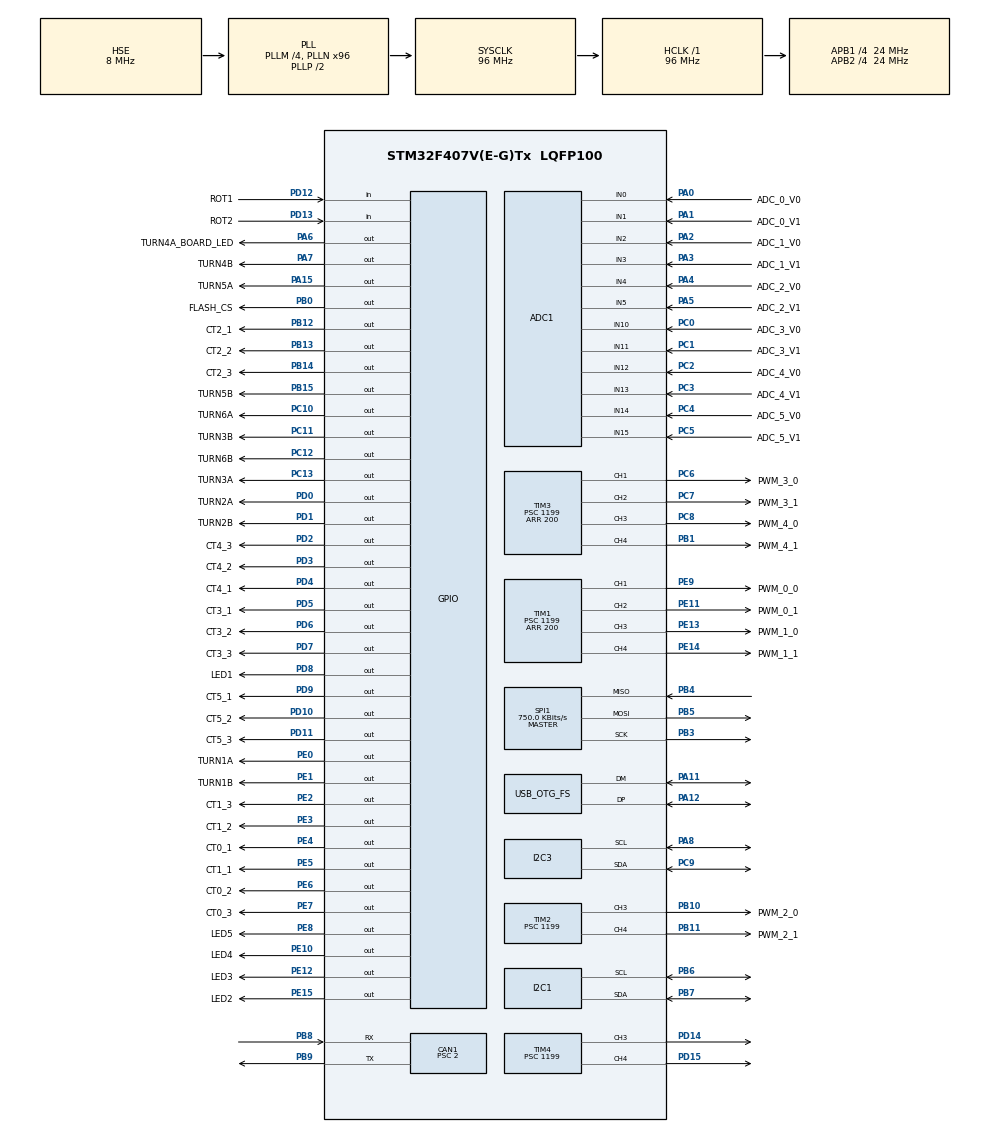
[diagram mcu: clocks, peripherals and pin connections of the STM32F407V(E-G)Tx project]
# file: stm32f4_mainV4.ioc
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ADC1.Channel-0\#ChannelRegularConversion=ADC_CHANNEL_0
ADC1.Channel-1\#ChannelRegularConversion=ADC_CHANNEL_1
ADC1.Channel-10\#ChannelRegularConversion=ADC_CHANNEL_14
ADC1.Channel-11\#ChannelRegularConversion=ADC_CHANNEL_15
ADC1.Channel-2\#ChannelRegularConversion=ADC_CHANNEL_2
ADC1.Channel-3\#ChannelRegularConversion=ADC_CHANNEL_3
ADC1.Channel-4\#ChannelRegularConversion=ADC_CHANNEL_4
ADC1.Channel-5\#ChannelRegularConversion=ADC_CHANNEL_5
ADC1.Channel-6\#ChannelRegularConversion=ADC_CHANNEL_10
ADC1.Channel-7\#ChannelRegularConversion=ADC_CHANNEL_11
ADC1.Channel-8\#ChannelRegularConversion=ADC_CHANNEL_12
ADC1.Channel-9\#ChannelRegularConversion=ADC_CHANNEL_13
ADC1.ClockPrescaler=ADC_CLOCK_SYNC_PCLK_DIV2
ADC1.DMAContinuousRequests=ENABLE
ADC1.EOCSelection=ADC_EOC_SEQ_CONV
ADC1.ExternalTrigConv=ADC_EXTERNALTRIGCONV_T8_TRGO
ADC1.ExternalTrigConvEdge=ADC_EXTERNALTRIGCONVEDGE_RISING
ADC1.NbrOfConversion=12
ADC1.NbrOfConversionFlag=1
ADC1.Rank-0\#ChannelRegularConversion=1
ADC1.Rank-1\#ChannelRegularConversion=2
ADC1.Rank-10\#ChannelRegularConversion=11
ADC1.Rank-11\#ChannelRegularConversion=12
ADC1.Rank-2\#ChannelRegularConversion=3
ADC1.Rank-3\#ChannelRegularConversion=4
ADC1.Rank-4\#ChannelRegularConversion=5
ADC1.Rank-5\#ChannelRegularConversion=6
ADC1.Rank-6\#ChannelRegularConversion=7
ADC1.Rank-7\#ChannelRegularConversion=8
ADC1.Rank-8\#ChannelRegularConversion=9
ADC1.Rank-9\#ChannelRegularConversion=10
ADC1.SamplingTime-0\#ChannelRegularConversion=ADC_SAMPLETIME_3CYCLES
ADC1.SamplingTime-1\#ChannelRegularConversion=ADC_SAMPLETIME_3CYCLES
ADC1.SamplingTime-10\#ChannelRegularConversion=ADC_SAMPLETIME_3CYCLES
ADC1.SamplingTime-11\#ChannelRegularConversion=ADC_SAMPLETIME_3CYCLES
ADC1.SamplingTime-2\#ChannelRegularConversion=ADC_SAMPLETIME_3CYCLES
ADC1.SamplingTime-3\#ChannelRegularConversion=ADC_SAMPLETIME_3CYCLES
ADC1.SamplingTime-4\#ChannelRegularConversion=ADC_SAMPLETIME_3CYCLES
ADC1.SamplingTime-5\#ChannelRegularConversion=ADC_SAMPLETIME_3CYCLES
ADC1.SamplingTime-6\#ChannelRegularConversion=ADC_SAMPLETIME_3CYCLES
ADC1.SamplingTime-7\#ChannelRegularConversion=ADC_SAMPLETIME_3CYCLES
ADC1.SamplingTime-8\#ChannelRegularConversion=ADC_SAMPLETIME_3CYCLES
ADC1.SamplingTime-9\#ChannelRegularConversion=ADC_SAMPLETIME_3CYCLES
ADC1.ScanConvMode=ENABLE
ADC1.master=1
ADC2.Channel-0\#ChannelRegularConversion=ADC_CHANNEL_0
ADC2.Channel-1\#ChannelRegularConversion=ADC_CHANNEL_1
ADC2.Channel-2\#ChannelRegularConversion=ADC_CHANNEL_2
ADC2.Channel-3\#ChannelRegularConversion=ADC_CHANNEL_3
ADC2.DMAContinuousRequests=DISABLE
ADC2.EOCSelection=ADC_EOC_SEQ_CONV
ADC2.ExternalTrigConv=ADC_SOFTWARE_START
ADC2.NbrOfConversion=4
ADC2.NbrOfConversionFlag=1
ADC2.Rank-0\#ChannelRegularConversion=1
ADC2.Rank-1\#ChannelRegularConversion=2
ADC2.Rank-2\#ChannelRegularConversion=3
ADC2.Rank-3\#ChannelRegularConversion=4
ADC2.SamplingTime-0\#ChannelRegularConversion=ADC_SAMPLETIME_3CYCLES
ADC2.SamplingTime-1\#ChannelRegularConversion=ADC_SAMPLETIME_3CYCLES
ADC2.SamplingTime-2\#ChannelRegularConversion=ADC_SAMPLETIME_3CYCLES
ADC2.SamplingTime-3\#ChannelRegularConversion=ADC_SAMPLETIME_3CYCLES
CAN1.ABOM=ENABLE
CAN1.AWUM=ENABLE
CAN1.BS1=CAN_BS1_10TQ
CAN1.CalculateBaudRate=1000000
CAN1.CalculateTimeBit=1000
CAN1.CalculateTimeQuantum=83.33333333333333
CAN1.NART=ENABLE
CAN1.Prescaler=2
CAN1.SJW=CAN_SJW_1TQ
Dma.ADC1.0.Direction=DMA_PERIPH_TO_MEMORY
Dma.ADC1.0.FIFOMode=DMA_FIFOMODE_DISABLE
Dma.ADC1.0.Instance=DMA2_Stream0
Dma.ADC1.0.MemDataAlignment=DMA_MDATAALIGN_HALFWORD
Dma.ADC1.0.MemInc=DMA_MINC_ENABLE
Dma.ADC1.0.Mode=DMA_CIRCULAR
Dma.ADC1.0.PeriphDataAlignment=DMA_PDATAALIGN_HALFWORD
Dma.ADC1.0.PeriphInc=DMA_PINC_DISABLE
Dma.ADC1.0.Priority=DMA_PRIORITY_HIGH
Dma.ADC2.1.Direction=DMA_PERIPH_TO_MEMORY
Dma.ADC2.1.FIFOMode=DMA_FIFOMODE_DISABLE
Dma.ADC2.1.Instance=DMA2_Stream2
Dma.ADC2.1.MemDataAlignment=DMA_MDATAALIGN_HALFWORD
Dma.ADC2.1.MemInc=DMA_MINC_ENABLE
Dma.ADC2.1.Mode=DMA_NORMAL
Dma.ADC2.1.PeriphDataAlignment=DMA_PDATAALIGN_HALFWORD
Dma.ADC2.1.PeriphInc=DMA_PINC_DISABLE
Dma.ADC2.1.Priority=DMA_PRIORITY_MEDIUM
Dma.Request0=ADC1
Dma.Request1=ADC2
FREERTOS.HEAP_NUMBER=1
FREERTOS.INCLUDE_uxTaskGetStackHighWaterMark=1
FREERTOS.INCLUDE_uxTaskGetStackHighWaterMark2=0
FREERTOS.INCLUDE_uxTaskPriorityGet=1
FREERTOS.INCLUDE_vTaskDelay=1
FREERTOS.INCLUDE_vTaskDelayUntil=1
FREERTOS.INCLUDE_vTaskDelete=0
FREERTOS.INCLUDE_vTaskPrioritySet=1
FREERTOS.INCLUDE_vTaskSuspend=1
FREERTOS.INCLUDE_xTaskGetHandle=0
FREERTOS.MEMORY_ALLOCATION=1
FREERTOS.Tasks01=uiTask,-1,256,StartUiTask,As weak,NULL,Static,defaultTaskBuffer,defaultTaskControlBlock;ctrlTask,2,256,StartCtrlTask,As external,NULL,Static,ctrlTaskBuffer,ctrlTaskControlBlock;usbTask,-2,384,StartUsbTask,As external,NULL,Static,usbTaskBuffer,usbTaskControlBlock;ina3221_task,1,172,ina3221_task_start,As weak,NULL,Static,ina3221_taskBuffer,ina3221_taskControlBlock;ledTask,3,128,start_led_task,As weak,NULL,Static,ledTaskBuffer,ledTaskControlBlock;oscillo,0,128,StartOscillo,As weak,NULL,Static,oscilloBuffer,oscilloControlBlock;oamTask,-2,256,StartOamTask,As external,NULL,Static,oamTaskBuffer,oamTaskControlBlock
FREERTOS.configCHECK_FOR_STACK_OVERFLOW=2
FREERTOS.configENABLE_BACKWARD_COMPATIBILITY=0
FREERTOS.configENABLE_FPU=0
FREERTOS.configGENERATE_RUN_TIME_STATS=1
FREERTOS.configIDLE_SHOULD_YIELD=0
FREERTOS.configRECORD_STACK_HIGH_ADDRESS=1
FREERTOS.configTOTAL_HEAP_SIZE=4096
FREERTOS.configUSE_MUTEXES=0
FREERTOS.configUSE_NEWLIB_REENTRANT=0
FREERTOS.configUSE_STATS_FORMATTING_FUNCTIONS=1
FREERTOS.configUSE_TRACE_FACILITY=1
FREERTOS.copyHeapFile=0
I2C1.I2C_Mode=I2C_Fast
I2C3.I2C_Mode=I2C_Fast
Mcu.Family=STM32F4
Mcu.Name=STM32F407V(E-G)Tx
Mcu.Package=LQFP100
NVIC.CAN1_RX0_IRQn=true\:5\:0\:false\:false\:true\:true\:true\:true\:true
NVIC.CAN1_RX1_IRQn=true\:5\:0\:false\:false\:true\:true\:true\:true\:true
NVIC.CAN1_SCE_IRQn=true\:5\:0\:false\:false\:true\:true\:true\:true\:true
NVIC.CAN1_TX_IRQn=true\:5\:0\:false\:false\:true\:true\:true\:true\:true
NVIC.DMA2_Stream0_IRQn=true\:5\:0\:true\:false\:true\:false\:false\:true\:true
NVIC.DMA2_Stream2_IRQn=true\:5\:0\:false\:false\:true\:true\:true\:true\:true
NVIC.I2C1_ER_IRQn=true\:5\:0\:false\:false\:true\:true\:true\:true\:true
NVIC.I2C1_EV_IRQn=true\:5\:0\:false\:false\:true\:true\:true\:true\:true
NVIC.OTG_FS_IRQn=true\:10\:0\:true\:false\:true\:false\:false\:true\:true
NVIC.PriorityGroup=NVIC_PRIORITYGROUP_4
NVIC.TIM1_UP_TIM10_IRQn=true\:5\:0\:true\:false\:true\:true\:true\:true\:true
NVIC.TIM5_IRQn=true\:7\:0\:true\:false\:true\:true\:true\:true\:true
NVIC.TIM7_IRQn=true\:15\:0\:false\:false\:true\:false\:false\:true\:true
NVIC.TimeBase=TIM7_IRQn
NVIC.TimeBaseIP=TIM7
PA0-WKUP.GPIO_Label=ADC_0_V0
PA0-WKUP.Signal=ADCx_IN0
PA1.GPIO_Label=ADC_0_V1
PA1.Signal=ADCx_IN1
PA11.Mode=Device_Only
PA11.Signal=USB_OTG_FS_DM
PA12.Mode=Device_Only
PA12.Signal=USB_OTG_FS_DP
PA13.Mode=Serial_Wire
PA13.Signal=SYS_JTMS-SWDIO
PA14.Mode=Serial_Wire
PA14.Signal=SYS_JTCK-SWCLK
PA15.GPIO_Label=TURN5A
PA15.Signal=GPIO_Output
PA2.GPIO_Label=ADC_1_V0
PA2.Signal=ADCx_IN2
PA3.GPIO_Label=ADC_1_V1
PA3.Signal=ADCx_IN3
PA4.GPIO_Label=ADC_2_V0
PA4.Signal=ADCx_IN4
PA5.GPIO_Label=ADC_2_V1
PA5.Signal=ADCx_IN5
PA6.GPIO_Label=TURN4A_BOARD_LED
PA6.Signal=GPIO_Output
PA7.GPIO_Label=TURN4B
PA7.Signal=GPIO_Output
PA8.Mode=I2C
PA8.Signal=I2C3_SCL
PB0.GPIO_Label=FLASH_CS
PB0.Signal=GPIO_Output
PB1.GPIO_Label=PWM_4_1
PB1.Signal=S_TIM3_CH4
PB10.GPIO_Label=PWM_2_0
PB10.Signal=S_TIM2_CH3
PB11.GPIO_Label=PWM_2_1
PB11.Signal=S_TIM2_CH4
PB12.GPIO_Label=CT2_1
PB12.Signal=GPIO_Output
PB13.GPIO_Label=CT2_2
PB13.Signal=GPIO_Output
PB14.GPIO_Label=CT2_3
PB14.Signal=GPIO_Output
PB15.GPIO_Label=TURN5B
PB15.Signal=GPIO_Output
PB3.Mode=Full_Duplex_Master
PB3.Signal=SPI1_SCK
PB4.Mode=Full_Duplex_Master
PB4.Signal=SPI1_MISO
PB5.Mode=Full_Duplex_Master
PB5.Signal=SPI1_MOSI
PB6.Mode=I2C
PB6.Signal=I2C1_SCL
PB7.Mode=I2C
PB7.Signal=I2C1_SDA
PB8.Mode=CAN_Activate
PB8.Signal=CAN1_RX
PB9.Mode=CAN_Activate
PB9.Signal=CAN1_TX
PC0.GPIO_Label=ADC_3_V0
PC0.Signal=ADCx_IN10
PC1.GPIO_Label=ADC_3_V1
PC1.Signal=ADCx_IN11
PC10.GPIO_Label=TURN6A
PC10.Signal=GPIO_Output
PC11.GPIO_Label=TURN3B
PC11.Signal=GPIO_Output
PC12.GPIO_Label=TURN6B
PC12.Signal=GPIO_Output
PC13-ANTI_TAMP.GPIO_Label=TURN3A
PC13-ANTI_TAMP.Signal=GPIO_Output
PC14-OSC32_IN.Mode=LSE-External-Oscillator
PC14-OSC32_IN.Signal=RCC_OSC32_IN
PC15-OSC32_OUT.Mode=LSE-External-Oscillator
PC15-OSC32_OUT.Signal=RCC_OSC32_OUT
PC2.GPIO_Label=ADC_4_V0
PC2.Signal=ADCx_IN12
PC3.GPIO_Label=ADC_4_V1
PC3.Signal=ADCx_IN13
PC4.GPIO_Label=ADC_5_V0
PC4.Signal=ADCx_IN14
PC5.GPIO_Label=ADC_5_V1
PC5.Signal=ADCx_IN15
PC6.GPIO_Label=PWM_3_0
PC6.Signal=S_TIM3_CH1
PC7.GPIO_Label=PWM_3_1
PC7.Signal=S_TIM3_CH2
PC8.GPIO_Label=PWM_4_0
PC8.Signal=S_TIM3_CH3
PC9.Mode=I2C
PC9.Signal=I2C3_SDA
PD0.GPIO_Label=TURN2A
PD0.Signal=GPIO_Output
PD1.GPIO_Label=TURN2B
PD1.Signal=GPIO_Output
PD10.GPIO_Label=CT5_2
PD10.Signal=GPIO_Output
PD11.GPIO_Label=CT5_3
PD11.Signal=GPIO_Output
PD12.GPIO_Label=ROT1
PD12.Signal=GPIO_Input
PD13.GPIO_Label=ROT2
PD13.Signal=GPIO_Input
PD14.Signal=S_TIM4_CH3
PD15.Signal=S_TIM4_CH4
PD2.GPIO_Label=CT4_3
PD2.Signal=GPIO_Output
PD3.GPIO_Label=CT4_2
PD3.Signal=GPIO_Output
PD4.GPIO_Label=CT4_1
PD4.Signal=GPIO_Output
PD5.GPIO_Label=CT3_1
PD5.Signal=GPIO_Output
PD6.GPIO_Label=CT3_2
PD6.Signal=GPIO_Output
PD7.GPIO_Label=CT3_3
PD7.Signal=GPIO_Output
PD8.GPIO_Label=LED1
PD8.Signal=GPIO_Output
PD9.GPIO_Label=CT5_1
PD9.Signal=GPIO_Output
PE0.GPIO_Label=TURN1A
PE0.Signal=GPIO_Output
PE1.GPIO_Label=TURN1B
PE1.Signal=GPIO_Output
PE10.GPIO_Label=LED4
PE10.Signal=GPIO_Output
PE11.GPIO_Label=PWM_0_1
PE11.Signal=S_TIM1_CH2
PE12.GPIO_Label=LED3
PE12.Signal=GPIO_Output
PE13.GPIO_Label=PWM_1_0
PE13.GPIO_Speed=GPIO_SPEED_FREQ_LOW
PE13.Signal=S_TIM1_CH3
PE14.GPIO_Label=PWM_1_1
PE14.GPIO_Speed=GPIO_SPEED_FREQ_LOW
PE14.Signal=S_TIM1_CH4
PE15.GPIO_Label=LED2
PE15.Signal=GPIO_Output
PE2.GPIO_Label=CT1_3
PE2.Signal=GPIO_Output
PE3.GPIO_Label=CT1_2
PE3.Signal=GPIO_Output
PE4.GPIO_Label=CT0_1
PE4.Signal=GPIO_Output
PE5.GPIO_Label=CT1_1
PE5.Signal=GPIO_Output
PE6.GPIO_Label=CT0_2
PE6.Signal=GPIO_Output
PE7.GPIO_Label=CT0_3
PE7.Signal=GPIO_Output
PE8.GPIO_Label=LED5
PE8.Signal=GPIO_Output
PE9.GPIO_Label=PWM_0_0
PE9.Signal=S_TIM1_CH1
PH0-OSC_IN.Mode=HSE-External-Oscillator
PH0-OSC_IN.Signal=RCC_OSC_IN
PH1-OSC_OUT.Mode=HSE-External-Oscillator
PH1-OSC_OUT.Signal=RCC_OSC_OUT
ProjectManager.HeapSize=0x200
ProjectManager.StackSize=0x400
ProjectManager.TargetToolchain=STM32CubeIDE
RCC.48MHZClocksFreq_Value=48000000
RCC.AHBFreq_Value=96000000
RCC.APB1CLKDivider=RCC_HCLK_DIV4
RCC.APB1Freq_Value=24000000
RCC.APB1TimFreq_Value=48000000
RCC.APB2CLKDivider=RCC_HCLK_DIV4
RCC.APB2Freq_Value=24000000
RCC.APB2TimFreq_Value=48000000
RCC.CortexFreq_Value=96000000
RCC.HCLKFreq_Value=96000000
RCC.HSE_VALUE=8000000
RCC.HSI_VALUE=16000000
RCC.PLLM=4
RCC.PLLN=96
RCC.RCC_RTC_Clock_Source=RCC_RTCCLKSOURCE_LSE
RCC.RCC_RTC_Clock_SourceVirtual=RCC_RTCCLKSOURCE_LSE
RCC.SYSCLKFreq_VALUE=96000000
RCC.SYSCLKSource=RCC_SYSCLKSOURCE_PLLCLK
RCC.VCOOutputFreq_Value=192000000
SH.ADCx_IN0.0=ADC1_IN0,IN0
SH.ADCx_IN0.1=ADC2_IN0,IN0
SH.ADCx_IN1.0=ADC1_IN1,IN1
SH.ADCx_IN1.1=ADC2_IN1,IN1
SH.ADCx_IN10.0=ADC1_IN10,IN10
SH.ADCx_IN11.0=ADC1_IN11,IN11
SH.ADCx_IN12.0=ADC1_IN12,IN12
SH.ADCx_IN13.0=ADC1_IN13,IN13
SH.ADCx_IN14.0=ADC1_IN14,IN14
SH.ADCx_IN15.0=ADC1_IN15,IN15
SH.ADCx_IN2.0=ADC1_IN2,IN2
SH.ADCx_IN2.1=ADC2_IN2,IN2
SH.ADCx_IN3.0=ADC1_IN3,IN3
SH.ADCx_IN3.1=ADC2_IN3,IN3
SH.ADCx_IN4.0=ADC1_IN4,IN4
SH.ADCx_IN5.0=ADC1_IN5,IN5
SH.S_TIM1_CH1.0=TIM1_CH1,PWM Generation1 CH1
SH.S_TIM1_CH2.0=TIM1_CH2,PWM Generation2 CH2
SH.S_TIM1_CH3.0=TIM1_CH3,PWM Generation3 CH3
SH.S_TIM1_CH4.0=TIM1_CH4,PWM Generation4 CH4
SH.S_TIM2_CH3.0=TIM2_CH3,PWM Generation3 CH3
SH.S_TIM2_CH4.0=TIM2_CH4,PWM Generation4 CH4
SH.S_TIM3_CH1.0=TIM3_CH1,PWM Generation1 CH1
SH.S_TIM3_CH2.0=TIM3_CH2,PWM Generation2 CH2
SH.S_TIM3_CH3.0=TIM3_CH3,PWM Generation3 CH3
SH.S_TIM3_CH4.0=TIM3_CH4,PWM Generation4 CH4
SH.S_TIM4_CH3.0=TIM4_CH3,PWM Generation3 CH3
SH.S_TIM4_CH4.0=TIM4_CH4,PWM Generation4 CH4
SPI1.BaudRatePrescaler=SPI_BAUDRATEPRESCALER_32
SPI1.CalculateBaudRate=750.0 KBits/s
SPI1.Direction=SPI_DIRECTION_2LINES
SPI1.Mode=SPI_MODE_MASTER
SPI1.VirtualType=VM_MASTER
TIM1.AutoReloadPreload=TIM_AUTORELOAD_PRELOAD_ENABLE
TIM1.Channel-PWM\ Generation1\ CH1=TIM_CHANNEL_1
TIM1.Channel-PWM\ Generation2\ CH2=TIM_CHANNEL_2
TIM1.Channel-PWM\ Generation3\ CH3=TIM_CHANNEL_3
TIM1.Channel-PWM\ Generation4\ CH4=TIM_CHANNEL_4
TIM1.CounterMode=TIM_COUNTERMODE_CENTERALIGNED3
TIM1.OffStateIDLEMode=TIM_OSSI_DISABLE
TIM1.Period=200
TIM1.Prescaler=1199
TIM1.TIM_MasterOutputTrigger=TIM_TRGO_UPDATE
TIM1.TIM_MasterSlaveMode=TIM_MASTERSLAVEMODE_ENABLE
TIM2.AutoReloadPreload=TIM_AUTORELOAD_PRELOAD_ENABLE
TIM2.Channel-PWM\ Generation3\ CH3=TIM_CHANNEL_3
TIM2.Channel-PWM\ Generation4\ CH4=TIM_CHANNEL_4
TIM2.CounterMode=TIM_COUNTERMODE_CENTERALIGNED3
TIM2.Period=200
TIM2.Prescaler=1199
TIM2.TIM_MasterOutputTrigger=TIM_TRGO_RESET
TIM2.TIM_MasterSlaveMode=TIM_MASTERSLAVEMODE_DISABLE
TIM3.AutoReloadPreload=TIM_AUTORELOAD_PRELOAD_ENABLE
TIM3.Channel-PWM\ Generation1\ CH1=TIM_CHANNEL_1
TIM3.Channel-PWM\ Generation2\ CH2=TIM_CHANNEL_2
TIM3.Channel-PWM\ Generation3\ CH3=TIM_CHANNEL_3
TIM3.Channel-PWM\ Generation4\ CH4=TIM_CHANNEL_4
TIM3.CounterMode=TIM_COUNTERMODE_CENTERALIGNED3
TIM3.Period=200
TIM3.Prescaler=1199
TIM3.TIM_MasterOutputTrigger=TIM_TRGO_RESET
TIM4.AutoReloadPreload=TIM_AUTORELOAD_PRELOAD_ENABLE
TIM4.Channel-PWM\ Generation3\ CH3=TIM_CHANNEL_3
TIM4.Channel-PWM\ Generation4\ CH4=TIM_CHANNEL_4
TIM4.CounterMode=TIM_COUNTERMODE_CENTERALIGNED3
TIM4.Period=200
TIM4.Prescaler=1199
TIM5.AutoReloadPreload=TIM_AUTORELOAD_PRELOAD_ENABLE
TIM5.Channel-Output\ Compare1\ No\ Output=TIM_CHANNEL_1
TIM5.OCMode_1=TIM_OCMODE_ACTIVE
TIM5.Period=10000
TIM5.Pulse-Output\ Compare1\ No\ Output=2900
TIM5.TIM_MasterOutputTrigger=TIM_TRGO_UPDATE
TIM5.TIM_MasterSlaveMode=TIM_MASTERSLAVEMODE_ENABLE
TIM8.AutoReloadPreload=TIM_AUTORELOAD_PRELOAD_ENABLE
TIM8.Period=199
TIM8.Prescaler=1199
TIM8.TIM_MasterOutputTrigger=TIM_TRGO_UPDATE
TIM8.TIM_MasterSlaveMode=TIM_MASTERSLAVEMODE_ENABLE
USB_DEVICE.APP_RX_DATA_SIZE-CDC_FS=512
USB_DEVICE.APP_TX_DATA_SIZE-CDC_FS=512
USB_DEVICE.CLASS_NAME_FS=CDC
USB_DEVICE.VirtualMode-CDC_FS=Cdc
USB_DEVICE.VirtualModeFS=Cdc_FS
USB_OTG_FS.VirtualMode=Device_Only
VP_FREERTOS_VS_CMSIS_V1.Mode=CMSIS_V1
VP_RTC_VS_RTC_Activate.Mode=RTC_Enabled
VP_RTC_VS_RTC_Calendar.Mode=RTC_Calendar
VP_SYS_VS_tim7.Mode=TIM7
VP_TIM12_VS_ClockSourceITR.Mode=TriggerSource_ITR0
VP_TIM1_VS_ClockSourceINT.Mode=Internal
VP_TIM2_VS_ClockSourceINT.Mode=Internal
VP_TIM2_VS_ClockSourceITR.Mode=TriggerSource_ITR0
VP_TIM3_VS_ClockSourceINT.Mode=Internal
VP_TIM3_VS_ClockSourceITR.Mode=TriggerSource_ITR0
VP_TIM3_VS_ControllerModeTrigger.Mode=Trigger Mode
VP_TIM4_VS_ClockSourceINT.Mode=Internal
VP_TIM5_VS_ClockSourceINT.Mode=Internal
VP_TIM5_VS_no_output1.Mode=Output Compare1 No Output
VP_TIM8_VS_ClockSourceINT.Mode=Internal
VP_TIM8_VS_ClockSourceITR.Mode=TriggerSource_ITR0
VP_TIM8_VS_ControllerModeReset.Mode=Reset Mode
VP_USB_DEVICE_VS_USB_DEVICE_CDC_FS.Mode=CDC_FS
board=custom

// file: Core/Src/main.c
/* USER CODE BEGIN Header */
/**
  ******************************************************************************
  * @file           : main.c
  * @brief          : Main program body
  ******************************************************************************
  * @attention
  *
  * <h2><center>&copy; Copyright (c) 2020 STMicroelectronics.
  * All rights reserved.</center></h2>
  *
  * This software component is licensed by ST under BSD 3-Clause license,
  * the "License"; You may not use this file except in compliance with the
  * License. You may obtain a copy of the License at:
  *                        opensource.org/licenses/BSD-3-Clause
  *
  ******************************************************************************
  */
/* USER CODE END Header */
#include "main.h"
#include "cmsis_os.h"
#include "usb_device.h"

/* USER CODE BEGIN Includes */
//#include "../../../disp_tft/ssd1306_tests.h"
//#include "../../../disp_tft/ssd1306.h"
//#include "../../../BLE/bletask.h"
#include <memory.h>

#include "trainctl_iface.h"
//#include "traincontrol.h"
//#include "canton.h"
//#include "stm32/txrxtask.h"
#include "stm32/usbtask.h"
//#include "stm32/taskauto.h"
#include "stm32/taskctrl.h"
#include "stm32/taskdisp.h"
//#include "../../../stm32dev/ina3221/ina3221.h"
#include "msg/notif.h"
#include "config/conf_canton.h"

/* USER CODE END Includes */

/* USER CODE BEGIN PTD */

volatile uint8_t oscillo_evtt1;

/* USER CODE END PTD */

ADC_HandleTypeDef hadc1;
ADC_HandleTypeDef hadc2;
DMA_HandleTypeDef hdma_adc1;
DMA_HandleTypeDef hdma_adc2;

CAN_HandleTypeDef hcan1;

I2C_HandleTypeDef hi2c1;
I2C_HandleTypeDef hi2c3;

RTC_HandleTypeDef hrtc;

SPI_HandleTypeDef hspi1;

TIM_HandleTypeDef htim1;
TIM_HandleTypeDef htim2;
TIM_HandleTypeDef htim3;
TIM_HandleTypeDef htim4;
TIM_HandleTypeDef htim5;
TIM_HandleTypeDef htim8;
TIM_HandleTypeDef htim12;

osThreadId uiTaskHandle;
uint32_t defaultTaskBuffer[ 256 ];
osStaticThreadDef_t defaultTaskControlBlock;
osThreadId ctrlTaskHandle;
uint32_t ctrlTaskBuffer[ 256 ];
osStaticThreadDef_t ctrlTaskControlBlock;
osThreadId usbTaskHandle;
uint32_t usbTaskBuffer[ 384 ];
osStaticThreadDef_t usbTaskControlBlock;
osThreadId ina3221_taskHandle;
uint32_t ina3221_taskBuffer[ 172 ];
osStaticThreadDef_t ina3221_taskControlBlock;
osThreadId ledTaskHandle;
uint32_t ledTaskBuffer[ 128 ];
osStaticThreadDef_t ledTaskControlBlock;
osThreadId oscilloHandle;
uint32_t oscilloBuffer[ 128 ];
osStaticThreadDef_t oscilloControlBlock;
osThreadId oamTaskHandle;
uint32_t oamTaskBuffer[ 256 ];
osStaticThreadDef_t oamTaskControlBlock;
/* USER CODE BEGIN PV */

uint32_t defaultTaskBuffer[] __attribute__((section(".ccmram")));
uint32_t ledTaskBuffer[] __attribute__((section(".ccmram")));
uint32_t oscilloBuffer[] __attribute__((section(".ccmram")));
uint32_t usbTaskBuffer[] __attribute__((section(".ccmram")));
uint32_t ina3221_taskBuffer[] __attribute__((section(".ccmram")));
uint32_t ctrlTaskBuffer[] __attribute__((section(".ccmram")));
uint32_t oamTaskBuffer[] __attribute__((section(".ccmram")));

/* USER CODE END PV */

void SystemClock_Config(void);
static void MX_GPIO_Init(void);
static void MX_DMA_Init(void);
static void MX_ADC1_Init(void);
static void MX_TIM1_Init(void);
static void MX_TIM2_Init(void);
static void MX_TIM3_Init(void);
static void MX_RTC_Init(void);
static void MX_TIM4_Init(void);
static void MX_TIM8_Init(void);
static void MX_TIM12_Init(void);
static void MX_CAN1_Init(void);
static void MX_ADC2_Init(void);
static void MX_TIM5_Init(void);
static void MX_SPI1_Init(void);
static void MX_I2C3_Init(void);
static void MX_I2C1_Init(void);
void StartUiTask(void const * argument);
extern void StartCtrlTask(void const * argument);
extern void StartUsbTask(void const * argument);
void ina3221_task_start(void const * argument);
void start_led_task(void const * argument);
void StartOscillo(void const * argument);
extern void StartOamTask(void const * argument);

/* USER CODE BEGIN PFP */

__weak void tim5_elapsed(void)
{

}
/* USER CODE END PFP */

/* USER CODE BEGIN 0 */
/*
uint32_t GetCurrentMicro(void)
{
  uint32_t m0 = HAL_GetTick();
  uint32_t u0 = SysTick->LOAD - SysTick->VAL;
  uint32_t m1 = HAL_GetTick();
  uint32_t u1 = SysTick->LOAD - SysTick->VAL;

  if (m1 > m0) {
    return ( m1 * 1000 + (u1 * 1000) / SysTick->LOAD);
  } else {
    return ( m0 * 1000 + (u0 * 1000) / SysTick->LOAD);
  }
}
*/

/* USER CODE END 0 */

int main(void)
{

  /* MCU Configuration--------------------------------------------------------*/

  /* Reset of all peripherals, Initializes the Flash interface and the Systick. */
  HAL_Init();

  /* Configure the system clock */
  SystemClock_Config();

  /* Initialize all configured peripherals */
  MX_GPIO_Init();
  MX_DMA_Init();
  MX_ADC1_Init();
  MX_TIM1_Init();
  MX_TIM2_Init();
  MX_TIM3_Init();
  MX_RTC_Init();
  MX_TIM4_Init();
  MX_TIM8_Init();
  MX_TIM12_Init();
  MX_CAN1_Init();
  MX_ADC2_Init();
  MX_TIM5_Init();
  MX_SPI1_Init();
  MX_I2C3_Init();
  MX_I2C1_Init();

  /* Create the thread(s) */
  /* definition and creation of uiTask */
  osThreadStaticDef(uiTask, StartUiTask, osPriorityBelowNormal, 0, 256, defaultTaskBuffer, &defaultTaskControlBlock);
  uiTaskHandle = osThreadCreate(osThread(uiTask), NULL);

  /* definition and creation of ctrlTask */
  osThreadStaticDef(ctrlTask, StartCtrlTask, osPriorityHigh, 0, 256, ctrlTaskBuffer, &ctrlTaskControlBlock);
  ctrlTaskHandle = osThreadCreate(osThread(ctrlTask), NULL);

  /* definition and creation of usbTask */
  osThreadStaticDef(usbTask, StartUsbTask, osPriorityLow, 0, 384, usbTaskBuffer, &usbTaskControlBlock);
  usbTaskHandle = osThreadCreate(osThread(usbTask), NULL);

  /* definition and creation of ina3221_task */
  osThreadStaticDef(ina3221_task, ina3221_task_start, osPriorityAboveNormal, 0, 172, ina3221_taskBuffer, &ina3221_taskControlBlock);
  ina3221_taskHandle = osThreadCreate(osThread(ina3221_task), NULL);

  /* definition and creation of ledTask */
  osThreadStaticDef(ledTask, start_led_task, osPriorityRealtime, 0, 128, ledTaskBuffer, &ledTaskControlBlock);
  ledTaskHandle = osThreadCreate(osThread(ledTask), NULL);

  /* definition and creation of oscillo */
  osThreadStaticDef(oscillo, StartOscillo, osPriorityNormal, 0, 128, oscilloBuffer, &oscilloControlBlock);
  oscilloHandle = osThreadCreate(osThread(oscillo), NULL);

  /* definition and creation of oamTask */
  osThreadStaticDef(oamTask, StartOamTask, osPriorityLow, 0, 256, oamTaskBuffer, &oamTaskControlBlock);
  oamTaskHandle = osThreadCreate(osThread(oamTask), NULL);

  /* Start scheduler */
  osKernelStart();

  /* We should never get here as control is now taken by the scheduler */
  /* Infinite loop */
  while (1)
  {

  }
}

void SystemClock_Config(void)
{
  RCC_OscInitTypeDef RCC_OscInitStruct = {0};
  RCC_ClkInitTypeDef RCC_ClkInitStruct = {0};

  /** Configure the main internal regulator output voltage
  */
  __HAL_RCC_PWR_CLK_ENABLE();
  __HAL_PWR_VOLTAGESCALING_CONFIG(PWR_REGULATOR_VOLTAGE_SCALE1);

  /** Initializes the RCC Oscillators according to the specified parameters
  * in the RCC_OscInitTypeDef structure.
  */
  RCC_OscInitStruct.OscillatorType = RCC_OSCILLATORTYPE_HSE|RCC_OSCILLATORTYPE_LSE;
  RCC_OscInitStruct.HSEState = RCC_HSE_ON;
  RCC_OscInitStruct.LSEState = RCC_LSE_ON;
  RCC_OscInitStruct.PLL.PLLState = RCC_PLL_ON;
  RCC_OscInitStruct.PLL.PLLSource = RCC_PLLSOURCE_HSE;
  RCC_OscInitStruct.PLL.PLLM = 4;
  RCC_OscInitStruct.PLL.PLLN = 96;
  RCC_OscInitStruct.PLL.PLLP = RCC_PLLP_DIV2;
  RCC_OscInitStruct.PLL.PLLQ = 4;
  if (HAL_RCC_OscConfig(&RCC_OscInitStruct) != HAL_OK)
  {
    Error_Handler();
  }

  /** Initializes the CPU, AHB and APB buses clocks
  */
  RCC_ClkInitStruct.ClockType = RCC_CLOCKTYPE_HCLK|RCC_CLOCKTYPE_SYSCLK
                              |RCC_CLOCKTYPE_PCLK1|RCC_CLOCKTYPE_PCLK2;
  RCC_ClkInitStruct.SYSCLKSource = RCC_SYSCLKSOURCE_PLLCLK;
  RCC_ClkInitStruct.AHBCLKDivider = RCC_SYSCLK_DIV1;
  RCC_ClkInitStruct.APB1CLKDivider = RCC_HCLK_DIV4;
  RCC_ClkInitStruct.APB2CLKDivider = RCC_HCLK_DIV4;

  if (HAL_RCC_ClockConfig(&RCC_ClkInitStruct, FLASH_LATENCY_3) != HAL_OK)
  {
    Error_Handler();
  }
}

static void MX_ADC1_Init(void)
{

  ADC_ChannelConfTypeDef sConfig = {0};

  /** Configure the global features of the ADC (Clock, Resolution, Data Alignment and number of conversion)
  */
  hadc1.Instance = ADC1;
  hadc1.Init.ClockPrescaler = ADC_CLOCK_SYNC_PCLK_DIV2;
  hadc1.Init.Resolution = ADC_RESOLUTION_12B;
  hadc1.Init.ScanConvMode = ENABLE;
  hadc1.Init.ContinuousConvMode = DISABLE;
  hadc1.Init.DiscontinuousConvMode = DISABLE;
  hadc1.Init.ExternalTrigConvEdge = ADC_EXTERNALTRIGCONVEDGE_RISING;
  hadc1.Init.ExternalTrigConv = ADC_EXTERNALTRIGCONV_T8_TRGO;
  hadc1.Init.DataAlign = ADC_DATAALIGN_RIGHT;
  hadc1.Init.NbrOfConversion = 12;
  hadc1.Init.DMAContinuousRequests = ENABLE;
  hadc1.Init.EOCSelection = ADC_EOC_SEQ_CONV;
  if (HAL_ADC_Init(&hadc1) != HAL_OK)
  {
    Error_Handler();
  }

  /** Configure for the selected ADC regular channel its corresponding rank in the sequencer and its sample time.
  */
  sConfig.Channel = ADC_CHANNEL_0;
  sConfig.Rank = 1;
  sConfig.SamplingTime = ADC_SAMPLETIME_3CYCLES;
  if (HAL_ADC_ConfigChannel(&hadc1, &sConfig) != HAL_OK)
  {
    Error_Handler();
  }

  /** Configure for the selected ADC regular channel its corresponding rank in the sequencer and its sample time.
  */
  sConfig.Channel = ADC_CHANNEL_1;
  sConfig.Rank = 2;
  if (HAL_ADC_ConfigChannel(&hadc1, &sConfig) != HAL_OK)
  {
    Error_Handler();
  }

  /** Configure for the selected ADC regular channel its corresponding rank in the sequencer and its sample time.
  */
  sConfig.Channel = ADC_CHANNEL_2;
  sConfig.Rank = 3;
  if (HAL_ADC_ConfigChannel(&hadc1, &sConfig) != HAL_OK)
  {
    Error_Handler();
  }

  /** Configure for the selected ADC regular channel its corresponding rank in the sequencer and its sample time.
  */
  sConfig.Channel = ADC_CHANNEL_3;
  sConfig.Rank = 4;
  if (HAL_ADC_ConfigChannel(&hadc1, &sConfig) != HAL_OK)
  {
    Error_Handler();
  }

  /** Configure for the selected ADC regular channel its corresponding rank in the sequencer and its sample time.
  */
  sConfig.Channel = ADC_CHANNEL_4;
  sConfig.Rank = 5;
  if (HAL_ADC_ConfigChannel(&hadc1, &sConfig) != HAL_OK)
  {
    Error_Handler();
  }

  /** Configure for the selected ADC regular channel its corresponding rank in the sequencer and its sample time.
  */
  sConfig.Channel = ADC_CHANNEL_5;
  sConfig.Rank = 6;
  if (HAL_ADC_ConfigChannel(&hadc1, &sConfig) != HAL_OK)
  {
    Error_Handler();
  }

  /** Configure for the selected ADC regular channel its corresponding rank in the sequencer and its sample time.
  */
  sConfig.Channel = ADC_CHANNEL_10;
  sConfig.Rank = 7;
  if (HAL_ADC_ConfigChannel(&hadc1, &sConfig) != HAL_OK)
  {
    Error_Handler();
  }

  /** Configure for the selected ADC regular channel its corresponding rank in the sequencer and its sample time.
  */
  sConfig.Channel = ADC_CHANNEL_11;
  sConfig.Rank = 8;
  if (HAL_ADC_ConfigChannel(&hadc1, &sConfig) != HAL_OK)
  {
    Error_Handler();
  }

  /** Configure for the selected ADC regular channel its corresponding rank in the sequencer and its sample time.
  */
  sConfig.Channel = ADC_CHANNEL_12;
  sConfig.Rank = 9;
  if (HAL_ADC_ConfigChannel(&hadc1, &sConfig) != HAL_OK)
  {
    Error_Handler();
  }

  /** Configure for the selected ADC regular channel its corresponding rank in the sequencer and its sample time.
  */
  sConfig.Channel = ADC_CHANNEL_13;
  sConfig.Rank = 10;
  if (HAL_ADC_ConfigChannel(&hadc1, &sConfig) != HAL_OK)
  {
    Error_Handler();
  }

  /** Configure for the selected ADC regular channel its corresponding rank in the sequencer and its sample time.
  */
  sConfig.Channel = ADC_CHANNEL_14;
  sConfig.Rank = 11;
  if (HAL_ADC_ConfigChannel(&hadc1, &sConfig) != HAL_OK)
  {
    Error_Handler();
  }

  /** Configure for the selected ADC regular channel its corresponding rank in the sequencer and its sample time.
  */
  sConfig.Channel = ADC_CHANNEL_15;
  sConfig.Rank = 12;
  if (HAL_ADC_ConfigChannel(&hadc1, &sConfig) != HAL_OK)
  {
    Error_Handler();
  }
  /* USER CODE BEGIN ADC1_Init 2 */
  if (hadc1.Init.NbrOfConversion != NUM_CANTONS*2) {
	    Error_Handler();
  }
  /* USER CODE END ADC1_Init 2 */

}

static void MX_ADC2_Init(void)
{

  ADC_ChannelConfTypeDef sConfig = {0};

  /** Configure the global features of the ADC (Clock, Resolution, Data Alignment and number of conversion)
  */
  hadc2.Instance = ADC2;
  hadc2.Init.ClockPrescaler = ADC_CLOCK_SYNC_PCLK_DIV2;
  hadc2.Init.Resolution = ADC_RESOLUTION_12B;
  hadc2.Init.ScanConvMode = ENABLE;
  hadc2.Init.ContinuousConvMode = DISABLE;
  hadc2.Init.DiscontinuousConvMode = DISABLE;
  hadc2.Init.ExternalTrigConvEdge = ADC_EXTERNALTRIGCONVEDGE_NONE;
  hadc2.Init.ExternalTrigConv = ADC_SOFTWARE_START;
  hadc2.Init.DataAlign = ADC_DATAALIGN_RIGHT;
  hadc2.Init.NbrOfConversion = 4;
  hadc2.Init.DMAContinuousRequests = DISABLE;
  hadc2.Init.EOCSelection = ADC_EOC_SEQ_CONV;
  if (HAL_ADC_Init(&hadc2) != HAL_OK)
  {
    Error_Handler();
  }

  /** Configure for the selected ADC regular channel its corresponding rank in the sequencer and its sample time.
  */
  sConfig.Channel = ADC_CHANNEL_0;
  sConfig.Rank = 1;
  sConfig.SamplingTime = ADC_SAMPLETIME_3CYCLES;
  if (HAL_ADC_ConfigChannel(&hadc2, &sConfig) != HAL_OK)
  {
    Error_Handler();
  }

  /** Configure for the selected ADC regular channel its corresponding rank in the sequencer and its sample time.
  */
  sConfig.Channel = ADC_CHANNEL_1;
  sConfig.Rank = 2;
  if (HAL_ADC_ConfigChannel(&hadc2, &sConfig) != HAL_OK)
  {
    Error_Handler();
  }

  /** Configure for the selected ADC regular channel its corresponding rank in the sequencer and its sample time.
  */
  sConfig.Channel = ADC_CHANNEL_2;
  sConfig.Rank = 3;
  if (HAL_ADC_ConfigChannel(&hadc2, &sConfig) != HAL_OK)
  {
    Error_Handler();
  }

  /** Configure for the selected ADC regular channel its corresponding rank in the sequencer and its sample time.
  */
  sConfig.Channel = ADC_CHANNEL_3;
  sConfig.Rank = 4;
  if (HAL_ADC_ConfigChannel(&hadc2, &sConfig) != HAL_OK)
  {
    Error_Handler();
  }

}

static void MX_CAN1_Init(void)
{

  hcan1.Instance = CAN1;
  hcan1.Init.Prescaler = 2;
  hcan1.Init.Mode = CAN_MODE_NORMAL;
  hcan1.Init.SyncJumpWidth = CAN_SJW_1TQ;
  hcan1.Init.TimeSeg1 = CAN_BS1_10TQ;
  hcan1.Init.TimeSeg2 = CAN_BS2_1TQ;
  hcan1.Init.TimeTriggeredMode = DISABLE;
  hcan1.Init.AutoBusOff = ENABLE;
  hcan1.Init.AutoWakeUp = ENABLE;
  hcan1.Init.AutoRetransmission = ENABLE;
  hcan1.Init.ReceiveFifoLocked = DISABLE;
  hcan1.Init.TransmitFifoPriority = DISABLE;
  if (HAL_CAN_Init(&hcan1) != HAL_OK)
  {
    Error_Handler();
  }

}

static void MX_I2C1_Init(void)
{

  hi2c1.Instance = I2C1;
  hi2c1.Init.ClockSpeed = 400000;
  hi2c1.Init.DutyCycle = I2C_DUTYCYCLE_2;
  hi2c1.Init.OwnAddress1 = 0;
  hi2c1.Init.AddressingMode = I2C_ADDRESSINGMODE_7BIT;
  hi2c1.Init.DualAddressMode = I2C_DUALADDRESS_DISABLE;
  hi2c1.Init.OwnAddress2 = 0;
  hi2c1.Init.GeneralCallMode = I2C_GENERALCALL_DISABLE;
  hi2c1.Init.NoStretchMode = I2C_NOSTRETCH_DISABLE;
  if (HAL_I2C_Init(&hi2c1) != HAL_OK)
  {
    Error_Handler();
  }

}

static void MX_I2C3_Init(void)
{

  hi2c3.Instance = I2C3;
  hi2c3.Init.ClockSpeed = 400000;
  hi2c3.Init.DutyCycle = I2C_DUTYCYCLE_2;
  hi2c3.Init.OwnAddress1 = 0;
  hi2c3.Init.AddressingMode = I2C_ADDRESSINGMODE_7BIT;
  hi2c3.Init.DualAddressMode = I2C_DUALADDRESS_DISABLE;
  hi2c3.Init.OwnAddress2 = 0;
  hi2c3.Init.GeneralCallMode = I2C_GENERALCALL_DISABLE;
  hi2c3.Init.NoStretchMode = I2C_NOSTRETCH_DISABLE;
  if (HAL_I2C_Init(&hi2c3) != HAL_OK)
  {
    Error_Handler();
  }

}

static void MX_RTC_Init(void)
{

  RTC_TimeTypeDef sTime = {0};
  RTC_DateTypeDef sDate = {0};

  /** Initialize RTC Only
  */
  hrtc.Instance = RTC;
  hrtc.Init.HourFormat = RTC_HOURFORMAT_24;
  hrtc.Init.AsynchPrediv = 127;
  hrtc.Init.SynchPrediv = 255;
  hrtc.Init.OutPut = RTC_OUTPUT_DISABLE;
  hrtc.Init.OutPutPolarity = RTC_OUTPUT_POLARITY_HIGH;
  hrtc.Init.OutPutType = RTC_OUTPUT_TYPE_OPENDRAIN;
  if (HAL_RTC_Init(&hrtc) != HAL_OK)
  {
    Error_Handler();
  }

  /* USER CODE BEGIN Check_RTC_BKUP */
  return;
  /* USER CODE END Check_RTC_BKUP */

  /** Initialize RTC and set the Time and Date
  */
  sTime.Hours = 0x0;
  sTime.Minutes = 0x0;
  sTime.Seconds = 0x0;
  sTime.DayLightSaving = RTC_DAYLIGHTSAVING_NONE;
  sTime.StoreOperation = RTC_STOREOPERATION_RESET;
  if (HAL_RTC_SetTime(&hrtc, &sTime, RTC_FORMAT_BCD) != HAL_OK)
  {
    Error_Handler();
  }
  sDate.WeekDay = RTC_WEEKDAY_MONDAY;
  sDate.Month = RTC_MONTH_JANUARY;
  sDate.Date = 0x1;
  sDate.Year = 0x0;

  if (HAL_RTC_SetDate(&hrtc, &sDate, RTC_FORMAT_BCD) != HAL_OK)
  {
    Error_Handler();
  }

}

static void MX_SPI1_Init(void)
{

  /* SPI1 parameter configuration*/
  hspi1.Instance = SPI1;
  hspi1.Init.Mode = SPI_MODE_MASTER;
  hspi1.Init.Direction = SPI_DIRECTION_2LINES;
  hspi1.Init.DataSize = SPI_DATASIZE_8BIT;
  hspi1.Init.CLKPolarity = SPI_POLARITY_LOW;
  hspi1.Init.CLKPhase = SPI_PHASE_1EDGE;
  hspi1.Init.NSS = SPI_NSS_SOFT;
  hspi1.Init.BaudRatePrescaler = SPI_BAUDRATEPRESCALER_32;
  hspi1.Init.FirstBit = SPI_FIRSTBIT_MSB;
  hspi1.Init.TIMode = SPI_TIMODE_DISABLE;
  hspi1.Init.CRCCalculation = SPI_CRCCALCULATION_DISABLE;
  hspi1.Init.CRCPolynomial = 10;
  if (HAL_SPI_Init(&hspi1) != HAL_OK)
  {
    Error_Handler();
  }

}

static void MX_TIM1_Init(void)
{

  TIM_ClockConfigTypeDef sClockSourceConfig = {0};
  TIM_MasterConfigTypeDef sMasterConfig = {0};
  TIM_OC_InitTypeDef sConfigOC = {0};
  TIM_BreakDeadTimeConfigTypeDef sBreakDeadTimeConfig = {0};

  htim1.Instance = TIM1;
  htim1.Init.Prescaler = 1199;
  htim1.Init.CounterMode = TIM_COUNTERMODE_CENTERALIGNED3;
  htim1.Init.Period = 200;
  htim1.Init.ClockDivision = TIM_CLOCKDIVISION_DIV1;
  htim1.Init.RepetitionCounter = 0;
  htim1.Init.AutoReloadPreload = TIM_AUTORELOAD_PRELOAD_ENABLE;
  if (HAL_TIM_Base_Init(&htim1) != HAL_OK)
  {
    Error_Handler();
  }
  sClockSourceConfig.ClockSource = TIM_CLOCKSOURCE_INTERNAL;
  if (HAL_TIM_ConfigClockSource(&htim1, &sClockSourceConfig) != HAL_OK)
  {
    Error_Handler();
  }
  if (HAL_TIM_PWM_Init(&htim1) != HAL_OK)
  {
    Error_Handler();
  }
  sMasterConfig.MasterOutputTrigger = TIM_TRGO_UPDATE;
  sMasterConfig.MasterSlaveMode = TIM_MASTERSLAVEMODE_ENABLE;
  if (HAL_TIMEx_MasterConfigSynchronization(&htim1, &sMasterConfig) != HAL_OK)
  {
    Error_Handler();
  }
  sConfigOC.OCMode = TIM_OCMODE_PWM1;
  sConfigOC.Pulse = 0;
  sConfigOC.OCPolarity = TIM_OCPOLARITY_HIGH;
  sConfigOC.OCNPolarity = TIM_OCNPOLARITY_HIGH;
  sConfigOC.OCFastMode = TIM_OCFAST_DISABLE;
  sConfigOC.OCIdleState = TIM_OCIDLESTATE_RESET;
  sConfigOC.OCNIdleState = TIM_OCNIDLESTATE_RESET;
  if (HAL_TIM_PWM_ConfigChannel(&htim1, &sConfigOC, TIM_CHANNEL_1) != HAL_OK)
  {
    Error_Handler();
  }
  if (HAL_TIM_PWM_ConfigChannel(&htim1, &sConfigOC, TIM_CHANNEL_2) != HAL_OK)
  {
    Error_Handler();
  }
  if (HAL_TIM_PWM_ConfigChannel(&htim1, &sConfigOC, TIM_CHANNEL_3) != HAL_OK)
  {
    Error_Handler();
  }
  if (HAL_TIM_PWM_ConfigChannel(&htim1, &sConfigOC, TIM_CHANNEL_4) != HAL_OK)
  {
    Error_Handler();
  }
  sBreakDeadTimeConfig.OffStateRunMode = TIM_OSSR_DISABLE;
  sBreakDeadTimeConfig.OffStateIDLEMode = TIM_OSSI_DISABLE;
  sBreakDeadTimeConfig.LockLevel = TIM_LOCKLEVEL_OFF;
  sBreakDeadTimeConfig.DeadTime = 0;
  sBreakDeadTimeConfig.BreakState = TIM_BREAK_DISABLE;
  sBreakDeadTimeConfig.BreakPolarity = TIM_BREAKPOLARITY_HIGH;
  sBreakDeadTimeConfig.AutomaticOutput = TIM_AUTOMATICOUTPUT_DISABLE;
  if (HAL_TIMEx_ConfigBreakDeadTime(&htim1, &sBreakDeadTimeConfig) != HAL_OK)
  {
    Error_Handler();
  }
  HAL_TIM_MspPostInit(&htim1);

}

static void MX_TIM2_Init(void)
{

  TIM_ClockConfigTypeDef sClockSourceConfig = {0};
  TIM_SlaveConfigTypeDef sSlaveConfig = {0};
  TIM_MasterConfigTypeDef sMasterConfig = {0};
  TIM_OC_InitTypeDef sConfigOC = {0};

  htim2.Instance = TIM2;
  htim2.Init.Prescaler = 1199;
  htim2.Init.CounterMode = TIM_COUNTERMODE_CENTERALIGNED3;
  htim2.Init.Period = 200;
  htim2.Init.ClockDivision = TIM_CLOCKDIVISION_DIV1;
  htim2.Init.AutoReloadPreload = TIM_AUTORELOAD_PRELOAD_ENABLE;
  if (HAL_TIM_Base_Init(&htim2) != HAL_OK)
  {
    Error_Handler();
  }
  sClockSourceConfig.ClockSource = TIM_CLOCKSOURCE_INTERNAL;
  if (HAL_TIM_ConfigClockSource(&htim2, &sClockSourceConfig) != HAL_OK)
  {
    Error_Handler();
  }
  if (HAL_TIM_PWM_Init(&htim2) != HAL_OK)
  {
    Error_Handler();
  }
  sSlaveConfig.SlaveMode = TIM_SLAVEMODE_DISABLE;
  sSlaveConfig.InputTrigger = TIM_TS_ITR0;
  if (HAL_TIM_SlaveConfigSynchro(&htim2, &sSlaveConfig) != HAL_OK)
  {
    Error_Handler();
  }
  sMasterConfig.MasterOutputTrigger = TIM_TRGO_RESET;
  sMasterConfig.MasterSlaveMode = TIM_MASTERSLAVEMODE_DISABLE;
  if (HAL_TIMEx_MasterConfigSynchronization(&htim2, &sMasterConfig) != HAL_OK)
  {
    Error_Handler();
  }
  sConfigOC.OCMode = TIM_OCMODE_PWM1;
  sConfigOC.Pulse = 0;
  sConfigOC.OCPolarity = TIM_OCPOLARITY_HIGH;
  sConfigOC.OCFastMode = TIM_OCFAST_DISABLE;
  if (HAL_TIM_PWM_ConfigChannel(&htim2, &sConfigOC, TIM_CHANNEL_3) != HAL_OK)
  {
    Error_Handler();
  }
  if (HAL_TIM_PWM_ConfigChannel(&htim2, &sConfigOC, TIM_CHANNEL_4) != HAL_OK)
  {
    Error_Handler();
  }
  HAL_TIM_MspPostInit(&htim2);

}

static void MX_TIM3_Init(void)
{

  TIM_ClockConfigTypeDef sClockSourceConfig = {0};
  TIM_SlaveConfigTypeDef sSlaveConfig = {0};
  TIM_MasterConfigTypeDef sMasterConfig = {0};
  TIM_OC_InitTypeDef sConfigOC = {0};

  htim3.Instance = TIM3;
  htim3.Init.Prescaler = 1199;
  htim3.Init.CounterMode = TIM_COUNTERMODE_CENTERALIGNED3;
  htim3.Init.Period = 200;
  htim3.Init.ClockDivision = TIM_CLOCKDIVISION_DIV1;
  htim3.Init.AutoReloadPreload = TIM_AUTORELOAD_PRELOAD_ENABLE;
  if (HAL_TIM_Base_Init(&htim3) != HAL_OK)
  {
    Error_Handler();
  }
  sClockSourceConfig.ClockSource = TIM_CLOCKSOURCE_INTERNAL;
  if (HAL_TIM_ConfigClockSource(&htim3, &sClockSourceConfig) != HAL_OK)
  {
    Error_Handler();
  }
  if (HAL_TIM_PWM_Init(&htim3) != HAL_OK)
  {
    Error_Handler();
  }
  sSlaveConfig.SlaveMode = TIM_SLAVEMODE_TRIGGER;
  sSlaveConfig.InputTrigger = TIM_TS_ITR0;
  if (HAL_TIM_SlaveConfigSynchro(&htim3, &sSlaveConfig) != HAL_OK)
  {
    Error_Handler();
  }
  sMasterConfig.MasterOutputTrigger = TIM_TRGO_RESET;
  sMasterConfig.MasterSlaveMode = TIM_MASTERSLAVEMODE_DISABLE;
  if (HAL_TIMEx_MasterConfigSynchronization(&htim3, &sMasterConfig) != HAL_OK)
  {
    Error_Handler();
  }
  sConfigOC.OCMode = TIM_OCMODE_PWM1;
  sConfigOC.Pulse = 0;
  sConfigOC.OCPolarity = TIM_OCPOLARITY_HIGH;
  sConfigOC.OCFastMode = TIM_OCFAST_DISABLE;
  if (HAL_TIM_PWM_ConfigChannel(&htim3, &sConfigOC, TIM_CHANNEL_1) != HAL_OK)
  {
    Error_Handler();
  }
  if (HAL_TIM_PWM_ConfigChannel(&htim3, &sConfigOC, TIM_CHANNEL_2) != HAL_OK)
  {
    Error_Handler();
  }
  if (HAL_TIM_PWM_ConfigChannel(&htim3, &sConfigOC, TIM_CHANNEL_3) != HAL_OK)
  {
    Error_Handler();
  }
  if (HAL_TIM_PWM_ConfigChannel(&htim3, &sConfigOC, TIM_CHANNEL_4) != HAL_OK)
  {
    Error_Handler();
  }
  HAL_TIM_MspPostInit(&htim3);

}

static void MX_TIM4_Init(void)
{

  TIM_ClockConfigTypeDef sClockSourceConfig = {0};
  TIM_MasterConfigTypeDef sMasterConfig = {0};
  TIM_OC_InitTypeDef sConfigOC = {0};

  htim4.Instance = TIM4;
  htim4.Init.Prescaler = 1199;
  htim4.Init.CounterMode = TIM_COUNTERMODE_CENTERALIGNED3;
  htim4.Init.Period = 200;
  htim4.Init.ClockDivision = TIM_CLOCKDIVISION_DIV1;
  htim4.Init.AutoReloadPreload = TIM_AUTORELOAD_PRELOAD_ENABLE;
  if (HAL_TIM_Base_Init(&htim4) != HAL_OK)
  {
    Error_Handler();
  }
  sClockSourceConfig.ClockSource = TIM_CLOCKSOURCE_INTERNAL;
  if (HAL_TIM_ConfigClockSource(&htim4, &sClockSourceConfig) != HAL_OK)
  {
    Error_Handler();
  }
  if (HAL_TIM_PWM_Init(&htim4) != HAL_OK)
  {
    Error_Handler();
  }
  sMasterConfig.MasterOutputTrigger = TIM_TRGO_RESET;
  sMasterConfig.MasterSlaveMode = TIM_MASTERSLAVEMODE_DISABLE;
  if (HAL_TIMEx_MasterConfigSynchronization(&htim4, &sMasterConfig) != HAL_OK)
  {
    Error_Handler();
  }
  sConfigOC.OCMode = TIM_OCMODE_PWM1;
  sConfigOC.Pulse = 0;
  sConfigOC.OCPolarity = TIM_OCPOLARITY_HIGH;
  sConfigOC.OCFastMode = TIM_OCFAST_DISABLE;
  if (HAL_TIM_PWM_ConfigChannel(&htim4, &sConfigOC, TIM_CHANNEL_3) != HAL_OK)
  {
    Error_Handler();
  }
  if (HAL_TIM_PWM_ConfigChannel(&htim4, &sConfigOC, TIM_CHANNEL_4) != HAL_OK)
  {
    Error_Handler();
  }
  HAL_TIM_MspPostInit(&htim4);

}

static void MX_TIM5_Init(void)
{

  TIM_ClockConfigTypeDef sClockSourceConfig = {0};
  TIM_MasterConfigTypeDef sMasterConfig = {0};
  TIM_OC_InitTypeDef sConfigOC = {0};

  htim5.Instance = TIM5;
  htim5.Init.Prescaler = 0;
  htim5.Init.CounterMode = TIM_COUNTERMODE_UP;
  htim5.Init.Period = 10000;
  htim5.Init.ClockDivision = TIM_CLOCKDIVISION_DIV1;
  htim5.Init.AutoReloadPreload = TIM_AUTORELOAD_PRELOAD_ENABLE;
  if (HAL_TIM_Base_Init(&htim5) != HAL_OK)
  {
    Error_Handler();
  }
  sClockSourceConfig.ClockSource = TIM_CLOCKSOURCE_INTERNAL;
  if (HAL_TIM_ConfigClockSource(&htim5, &sClockSourceConfig) != HAL_OK)
  {
    Error_Handler();
  }
  if (HAL_TIM_OC_Init(&htim5) != HAL_OK)
  {
    Error_Handler();
  }
  sMasterConfig.MasterOutputTrigger = TIM_TRGO_UPDATE;
  sMasterConfig.MasterSlaveMode = TIM_MASTERSLAVEMODE_ENABLE;
  if (HAL_TIMEx_MasterConfigSynchronization(&htim5, &sMasterConfig) != HAL_OK)
  {
    Error_Handler();
  }
  sConfigOC.OCMode = TIM_OCMODE_ACTIVE;
  sConfigOC.Pulse = 2900;
  sConfigOC.OCPolarity = TIM_OCPOLARITY_HIGH;
  sConfigOC.OCFastMode = TIM_OCFAST_DISABLE;
  if (HAL_TIM_OC_ConfigChannel(&htim5, &sConfigOC, TIM_CHANNEL_1) != HAL_OK)
  {
    Error_Handler();
  }

}

static void MX_TIM8_Init(void)
{

  TIM_ClockConfigTypeDef sClockSourceConfig = {0};
  TIM_SlaveConfigTypeDef sSlaveConfig = {0};
  TIM_MasterConfigTypeDef sMasterConfig = {0};

  htim8.Instance = TIM8;
  htim8.Init.Prescaler = 1199;
  htim8.Init.CounterMode = TIM_COUNTERMODE_UP;
  htim8.Init.Period = 199;
  htim8.Init.ClockDivision = TIM_CLOCKDIVISION_DIV1;
  htim8.Init.RepetitionCounter = 0;
  htim8.Init.AutoReloadPreload = TIM_AUTORELOAD_PRELOAD_ENABLE;
  if (HAL_TIM_Base_Init(&htim8) != HAL_OK)
  {
    Error_Handler();
  }
  sClockSourceConfig.ClockSource = TIM_CLOCKSOURCE_INTERNAL;
  if (HAL_TIM_ConfigClockSource(&htim8, &sClockSourceConfig) != HAL_OK)
  {
    Error_Handler();
  }
  sSlaveConfig.SlaveMode = TIM_SLAVEMODE_RESET;
  sSlaveConfig.InputTrigger = TIM_TS_ITR0;
  if (HAL_TIM_SlaveConfigSynchro(&htim8, &sSlaveConfig) != HAL_OK)
  {
    Error_Handler();
  }
  sMasterConfig.MasterOutputTrigger = TIM_TRGO_UPDATE;
  sMasterConfig.MasterSlaveMode = TIM_MASTERSLAVEMODE_ENABLE;
  if (HAL_TIMEx_MasterConfigSynchronization(&htim8, &sMasterConfig) != HAL_OK)
  {
    Error_Handler();
  }

}

static void MX_TIM12_Init(void)
{

  TIM_SlaveConfigTypeDef sSlaveConfig = {0};

  htim12.Instance = TIM12;
  htim12.Init.Prescaler = 0;
  htim12.Init.CounterMode = TIM_COUNTERMODE_UP;
  htim12.Init.Period = 65535;
  htim12.Init.ClockDivision = TIM_CLOCKDIVISION_DIV1;
  htim12.Init.AutoReloadPreload = TIM_AUTORELOAD_PRELOAD_DISABLE;
  if (HAL_TIM_Base_Init(&htim12) != HAL_OK)
  {
    Error_Handler();
  }
  sSlaveConfig.SlaveMode = TIM_SLAVEMODE_DISABLE;
  sSlaveConfig.InputTrigger = TIM_TS_ITR0;
  if (HAL_TIM_SlaveConfigSynchro(&htim12, &sSlaveConfig) != HAL_OK)
  {
    Error_Handler();
  }

}

static void MX_DMA_Init(void)
{

  /* DMA controller clock enable */
  __HAL_RCC_DMA2_CLK_ENABLE();

  /* DMA interrupt init */
  /* DMA2_Stream0_IRQn interrupt configuration */
  HAL_NVIC_SetPriority(DMA2_Stream0_IRQn, 5, 0);
  HAL_NVIC_EnableIRQ(DMA2_Stream0_IRQn);
  /* DMA2_Stream2_IRQn interrupt configuration */
  HAL_NVIC_SetPriority(DMA2_Stream2_IRQn, 5, 0);
  HAL_NVIC_EnableIRQ(DMA2_Stream2_IRQn);

}

static void MX_GPIO_Init(void)
{
  GPIO_InitTypeDef GPIO_InitStruct = {0};

  /* GPIO Ports Clock Enable */
  __HAL_RCC_GPIOE_CLK_ENABLE();
  __HAL_RCC_GPIOC_CLK_ENABLE();
  __HAL_RCC_GPIOH_CLK_ENABLE();
  __HAL_RCC_GPIOA_CLK_ENABLE();
  __HAL_RCC_GPIOB_CLK_ENABLE();
  __HAL_RCC_GPIOD_CLK_ENABLE();

  /*Configure GPIO pin Output Level */
  HAL_GPIO_WritePin(GPIOE, CT1_3_Pin|CT1_2_Pin|CT0_1_Pin|CT1_1_Pin
                          |CT0_2_Pin|CT0_3_Pin|LED5_Pin|LED4_Pin
                          |LED3_Pin|LED2_Pin|TURN1A_Pin|TURN1B_Pin, GPIO_PIN_RESET);

  /*Configure GPIO pin Output Level */
  HAL_GPIO_WritePin(GPIOC, TURN3A_Pin|TURN6A_Pin|TURN3B_Pin|TURN6B_Pin, GPIO_PIN_RESET);

  /*Configure GPIO pin Output Level */
  HAL_GPIO_WritePin(GPIOA, TURN4A_BOARD_LED_Pin|TURN4B_Pin|TURN5A_Pin, GPIO_PIN_RESET);

  /*Configure GPIO pin Output Level */
  HAL_GPIO_WritePin(GPIOB, FLASH_CS_Pin|CT2_1_Pin|CT2_2_Pin|CT2_3_Pin
                          |TURN5B_Pin, GPIO_PIN_RESET);

  /*Configure GPIO pin Output Level */
  HAL_GPIO_WritePin(GPIOD, LED1_Pin|CT5_1_Pin|CT5_2_Pin|CT5_3_Pin
                          |TURN2A_Pin|TURN2B_Pin|CT4_3_Pin|CT4_2_Pin
                          |CT4_1_Pin|CT3_1_Pin|CT3_2_Pin|CT3_3_Pin, GPIO_PIN_RESET);

  /*Configure GPIO pins : CT1_3_Pin CT1_2_Pin CT0_1_Pin CT1_1_Pin
                           CT0_2_Pin CT0_3_Pin LED5_Pin LED4_Pin
                           LED3_Pin LED2_Pin TURN1A_Pin TURN1B_Pin */
  GPIO_InitStruct.Pin = CT1_3_Pin|CT1_2_Pin|CT0_1_Pin|CT1_1_Pin
                          |CT0_2_Pin|CT0_3_Pin|LED5_Pin|LED4_Pin
                          |LED3_Pin|LED2_Pin|TURN1A_Pin|TURN1B_Pin;
  GPIO_InitStruct.Mode = GPIO_MODE_OUTPUT_PP;
  GPIO_InitStruct.Pull = GPIO_NOPULL;
  GPIO_InitStruct.Speed = GPIO_SPEED_FREQ_LOW;
  HAL_GPIO_Init(GPIOE, &GPIO_InitStruct);

  /*Configure GPIO pins : TURN3A_Pin TURN6A_Pin TURN3B_Pin TURN6B_Pin */
  GPIO_InitStruct.Pin = TURN3A_Pin|TURN6A_Pin|TURN3B_Pin|TURN6B_Pin;
  GPIO_InitStruct.Mode = GPIO_MODE_OUTPUT_PP;
  GPIO_InitStruct.Pull = GPIO_NOPULL;
  GPIO_InitStruct.Speed = GPIO_SPEED_FREQ_LOW;
  HAL_GPIO_Init(GPIOC, &GPIO_InitStruct);

  /*Configure GPIO pins : TURN4A_BOARD_LED_Pin TURN4B_Pin TURN5A_Pin */
  GPIO_InitStruct.Pin = TURN4A_BOARD_LED_Pin|TURN4B_Pin|TURN5A_Pin;
  GPIO_InitStruct.Mode = GPIO_MODE_OUTPUT_PP;
  GPIO_InitStruct.Pull = GPIO_NOPULL;
  GPIO_InitStruct.Speed = GPIO_SPEED_FREQ_LOW;
  HAL_GPIO_Init(GPIOA, &GPIO_InitStruct);

  /*Configure GPIO pins : FLASH_CS_Pin CT2_1_Pin CT2_2_Pin CT2_3_Pin
                           TURN5B_Pin */
  GPIO_InitStruct.Pin = FLASH_CS_Pin|CT2_1_Pin|CT2_2_Pin|CT2_3_Pin
                          |TURN5B_Pin;
  GPIO_InitStruct.Mode = GPIO_MODE_OUTPUT_PP;
  GPIO_InitStruct.Pull = GPIO_NOPULL;
  GPIO_InitStruct.Speed = GPIO_SPEED_FREQ_LOW;
  HAL_GPIO_Init(GPIOB, &GPIO_InitStruct);

  /*Configure GPIO pins : LED1_Pin CT5_1_Pin CT5_2_Pin CT5_3_Pin
                           TURN2A_Pin TURN2B_Pin CT4_3_Pin CT4_2_Pin
                           CT4_1_Pin CT3_1_Pin CT3_2_Pin CT3_3_Pin */
  GPIO_InitStruct.Pin = LED1_Pin|CT5_1_Pin|CT5_2_Pin|CT5_3_Pin
                          |TURN2A_Pin|TURN2B_Pin|CT4_3_Pin|CT4_2_Pin
                          |CT4_1_Pin|CT3_1_Pin|CT3_2_Pin|CT3_3_Pin;
  GPIO_InitStruct.Mode = GPIO_MODE_OUTPUT_PP;
  GPIO_InitStruct.Pull = GPIO_NOPULL;
  GPIO_InitStruct.Speed = GPIO_SPEED_FREQ_LOW;
  HAL_GPIO_Init(GPIOD, &GPIO_InitStruct);

  /*Configure GPIO pins : ROT1_Pin ROT2_Pin */
  GPIO_InitStruct.Pin = ROT1_Pin|ROT2_Pin;
  GPIO_InitStruct.Mode = GPIO_MODE_INPUT;
  GPIO_InitStruct.Pull = GPIO_NOPULL;
  HAL_GPIO_Init(GPIOD, &GPIO_InitStruct);

}

__weak void StartUiTask(void const * argument)
{
  /* init code for USB_DEVICE */
  MX_USB_DEVICE_Init();
  /* USER CODE BEGIN 5 */
  (void) argument; // unused
    //RunBleTask(&huart4, &hdma_uart4_rx, &hdma_uart4_tx, bleRespQueueHandle);
#if 0
	for (;;) {
		/* Infinite loop */
#define MSG "AT\r\nAT+NAME?\r\n"
		//HAL_UART_Transmit(&huart4, MSG, sizeof(MSG), 100);
		__HAL_UART_ENABLE_IT(&huart4, UART_IT_IDLE );
		__HAL_DMA_ENABLE_IT(&hdma_uart4_rx, DMA_IT_TC);
		tx_on_progress=1;
		HAL_UART_Transmit_DMA(&huart4, (uint8_t *)MSG, strlen(MSG));
		while (tx_on_progress) {

		}
		if (rx_on_progress) {
			osDelay(100);
			continue;
		}
		rx_on_progress = 1;
		HAL_UART_Receive_DMA(&huart4, buf, sizeof(buf));
		/*while (rx_on_progress) {

				}*/
		osDelay(3000);
	}
#endif

#if 1
	//ina3221_init();

	taskdisp();

#else
  for(;;)
  {
      HAL_GPIO_TogglePin(GPIOA,GPIO_PIN_6);
      osDelay(500);
      HAL_GPIO_TogglePin(GPIOA,GPIO_PIN_7);
      osDelay(500);
   	  HAL_GPIO_TogglePin(GPIOC, GPIO_PIN_13);
   	  ssd1306_TestAll();
      osDelay(1000);
  }
#endif
  /* USER CODE END 5 */
}

__weak void ina3221_task_start(void const * argument)
{
  /* USER CODE BEGIN ina3221_task_start */
  /* Infinite loop */
	(void) argument;
  for(;;)
  {
    osDelay(1);
  }
  /* USER CODE END ina3221_task_start */
}

__weak void start_led_task(void const * argument)
{
  /* USER CODE BEGIN start_led_task */
  /* Infinite loop */
	(void) argument;
  for(;;)
  {
    osDelay(1);
  }
  /* USER CODE END start_led_task */
}

__weak void StartOscillo(void const * argument)
{
  /* USER CODE BEGIN StartOscillo */
	(void) argument;
  /* Infinite loop */
  for(;;)
  {
    osDelay(1);
  }
  /* USER CODE END StartOscillo */
}

void HAL_TIM_PeriodElapsedCallback(TIM_HandleTypeDef *htim)
{
  if (htim->Instance == TIM7) {
    HAL_IncTick();
  }
  /* USER CODE BEGIN Callback 1 */

  if (htim->Instance == TIM5) {
	  tim5_elapsed();
  }
  if (htim->Instance == TIM8) {
	  itm_debug1(DBG_TIM, "tim8",0);
  }
  if (htim->Instance == TIM1) {
	  //static int igncnt=0;
	  static uint32_t lasttick = 0;
	  uint32_t t1 = __HAL_TIM_GET_COUNTER(&htim1);
	  uint32_t t = HAL_GetTick();
	  if ((t1<50) && (t >= lasttick+5)) { // not faster than 50Hz (20ms), whatever the frequency is
		 lasttick = t;
		  oscillo_evtt1 = 1+t1;

		  BaseType_t higher=0;
		  xTaskNotifyFromISR(ina3221_taskHandle, NOTIF_INA_READ, eSetBits, &higher);
		  portYIELD_FROM_ISR(higher);

	  }

	  /* SWJ
	  if ((0)) {
		  static uint32_t lasttick = 0;
		  if (t >= lasttick+5000) { // not faster than 20Hz, whatever the frequency is
			  lasttick = t;
			  uint32_t t1 = __HAL_TIM_GET_COUNTER(&htim1);
			  uint32_t t2 = __HAL_TIM_GET_COUNTER(&htim2);
			  uint32_t t3 = __HAL_TIM_GET_COUNTER(&htim3);
			  uint32_t t4 = __HAL_TIM_GET_COUNTER(&htim4);
			  uint32_t t8 = __HAL_TIM_GET_COUNTER(&htim8);
			  uint32_t t12 = __HAL_TIM_GET_COUNTER(&htim12);
			  HAL_TIM_StateTypeDef s1 = HAL_TIM_PWM_GetState(&htim1);
			  HAL_TIM_StateTypeDef s2 = HAL_TIM_PWM_GetState(&htim2);
			  HAL_TIM_StateTypeDef s3 = HAL_TIM_PWM_GetState(&htim3);
			  HAL_TIM_StateTypeDef s4 = HAL_TIM_PWM_GetState(&htim4);
			  HAL_TIM_StateTypeDef s8 = HAL_TIM_PWM_GetState(&htim8);
			  HAL_TIM_StateTypeDef s12 = HAL_TIM_PWM_GetState(&htim12);

			  itm_debug3(DBG_TIM,"tim", t1, t2, t3);
		  }
	  }
	  */

  }
  /* USER CODE END Callback 1 */
}

void Error_Handler(void)
{
  /* USER CODE BEGIN Error_Handler_Debug */
  /* User can add his own implementation to report the HAL error return state */
	FatalError("EH", "Error_Handler", Error_Other);
	for (;;) {

	}
  /* USER CODE END Error_Handler_Debug */
}

#ifdef  USE_FULL_ASSERT
/**
  * @brief  Reports the name of the source file and the source line number
  *         where the assert_param error has occurred.
  * @param  file: pointer to the source file name
  * @param  line: assert_param error line source number
  * @retval None
  */
void assert_failed(uint8_t *file, uint32_t line)
{
  /* USER CODE BEGIN 6 */
	Error_Handler();
  /* User can add his own implementation to report the file name and line number,
     tex: printf("Wrong parameters value: file %s on line %d\r\n", file, line) */
  /* USER CODE END 6 */
}
#endif /* USE_FULL_ASSERT */

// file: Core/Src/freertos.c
/* USER CODE BEGIN Header */
/**
  ******************************************************************************
  * File Name          : freertos.c
  * Description        : Code for freertos applications
  ******************************************************************************
  * @attention
  *
  * <h2><center>&copy; Copyright (c) 2020 STMicroelectronics.
  * All rights reserved.</center></h2>
  *
  * This software component is licensed by ST under Ultimate Liberty license
  * SLA0044, the "License"; You may not use this file except in compliance with
  * the License. You may obtain a copy of the License at:
  *                             www.st.com/SLA0044
  *
  ******************************************************************************
  */
/* USER CODE END Header */

#include "FreeRTOS.h"
#include "task.h"
#include "main.h"

/* GetIdleTaskMemory prototype (linked to static allocation support) */
void vApplicationGetIdleTaskMemory( StaticTask_t **ppxIdleTaskTCBBuffer, StackType_t **ppxIdleTaskStackBuffer, uint32_t *pulIdleTaskStackSize );

/* Hook prototypes */
void configureTimerForRunTimeStats(void);
unsigned long getRunTimeCounterValue(void);
void vApplicationStackOverflowHook(TaskHandle_t xTask, signed char *pcTaskName);

/* USER CODE BEGIN 1 */
/* Functions needed when configGENERATE_RUN_TIME_STATS is on */
__weak void configureTimerForRunTimeStats(void)
{

}

__weak unsigned long getRunTimeCounterValue(void)
{
return 0;
}
/* USER CODE END 1 */

/* USER CODE BEGIN 4 */
__weak void vApplicationStackOverflowHook(TaskHandle_t xTask, signed char *pcTaskName)
{
   /* Run time stack overflow checking is performed if
   configCHECK_FOR_STACK_OVERFLOW is defined to 1 or 2. This hook function is
   called if a stack overflow is detected. */
}
/* USER CODE END 4 */

/* USER CODE BEGIN GET_IDLE_TASK_MEMORY */
static StaticTask_t xIdleTaskTCBBuffer;
static StackType_t xIdleStack[configMINIMAL_STACK_SIZE];

void vApplicationGetIdleTaskMemory( StaticTask_t **ppxIdleTaskTCBBuffer, StackType_t **ppxIdleTaskStackBuffer, uint32_t *pulIdleTaskStackSize )
{
  *ppxIdleTaskTCBBuffer = &xIdleTaskTCBBuffer;
  *ppxIdleTaskStackBuffer = &xIdleStack[0];
  *pulIdleTaskStackSize = configMINIMAL_STACK_SIZE;
  /* place for user code */
}
/* USER CODE END GET_IDLE_TASK_MEMORY */
